AUTOSAR XML
package /AccSwcs
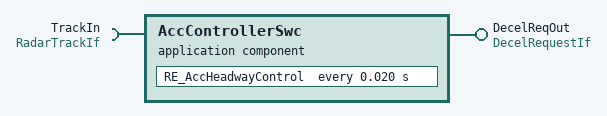
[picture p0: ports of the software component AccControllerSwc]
  application sw component type AccControllerSwc
    require port TrackIn: required-interface=RadarTrackIf
    provide port DecelReqOut: provided-interface=DecelRequestIf
    behavior AccController_IB
      runnable RE_AccHeadwayControl: execution-time-wcet=0.0032
      timing event TE_Acc_20ms: start-on-event=RE_AccHeadwayControl, period=0.020
